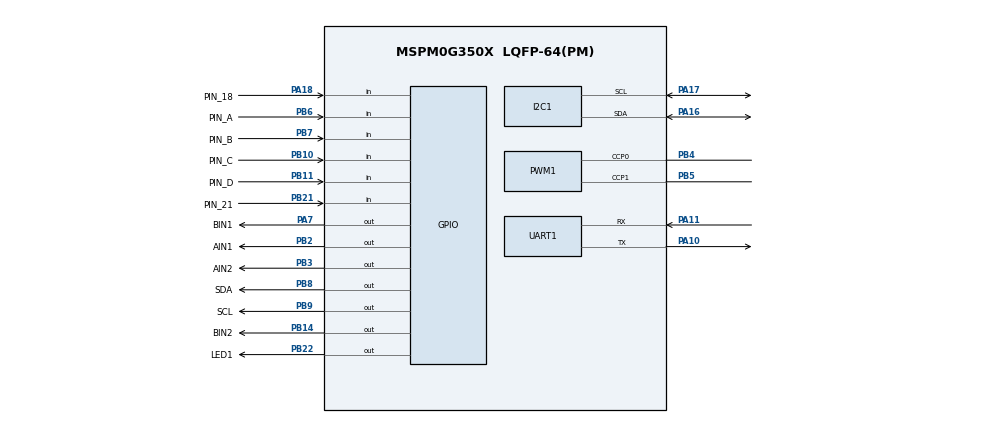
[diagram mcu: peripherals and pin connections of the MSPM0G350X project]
/**
 * @cliArgs --device "MSPM0G350X" --part "Default" --package "LQFP-64(PM)" --product "mspm0_sdk@2.03.00.07"
 * @versions {"tool":"1.22.0+3893"}
 */

/**
 * Import the modules used in this configuration.
 */
const GPIO    = scripting.addModule("/ti/driverlib/GPIO", {}, false);
const GPIO1   = GPIO.addInstance();
const GPIO2   = GPIO.addInstance();
const GPIO3   = GPIO.addInstance();
const GPIO4   = GPIO.addInstance();
const GPIO5   = GPIO.addInstance();
const I2C     = scripting.addModule("/ti/driverlib/I2C", {}, false);
const I2C1    = I2C.addInstance();
const PWM     = scripting.addModule("/ti/driverlib/PWM", {}, false);
const PWM1    = PWM.addInstance();
const SYSCTL  = scripting.addModule("/ti/driverlib/SYSCTL");
const SYSTICK = scripting.addModule("/ti/driverlib/SYSTICK");
const TIMER   = scripting.addModule("/ti/driverlib/TIMER", {}, false);
const TIMER1  = TIMER.addInstance();
const UART    = scripting.addModule("/ti/driverlib/UART", {}, false);
const UART1   = UART.addInstance();

/**
 * Write custom configuration values to the imported modules.
 */
const gate7  = system.clockTree["MFCLKGATE"];
gate7.enable = true;

GPIO1.$name                              = "LED";
GPIO1.associatedPins[0].internalResistor = "PULL_DOWN";
GPIO1.associatedPins[0].$name            = "LED1";
GPIO1.associatedPins[0].assignedPin      = "22";
GPIO1.associatedPins[0].pin.$assign      = "PB22";

const Board = scripting.addModule("/ti/driverlib/Board", {}, false);

GPIO2.$name                              = "KEY";
GPIO2.associatedPins.create(2);
GPIO2.associatedPins[0].$name            = "PIN_18";
GPIO2.associatedPins[0].direction        = "INPUT";
GPIO2.associatedPins[0].assignedPin      = "18";
GPIO2.associatedPins[0].internalResistor = "PULL_DOWN";
GPIO2.associatedPins[0].interruptEn      = true;
GPIO2.associatedPins[0].polarity         = "RISE";
GPIO2.associatedPins[0].assignedPort     = "PORTA";
GPIO2.associatedPins[0].pin.$assign      = "PA18";
GPIO2.associatedPins[1].$name            = "PIN_21";
GPIO2.associatedPins[1].direction        = "INPUT";
GPIO2.associatedPins[1].assignedPort     = "PORTB";
GPIO2.associatedPins[1].assignedPin      = "21";
GPIO2.associatedPins[1].internalResistor = "PULL_UP";
GPIO2.associatedPins[1].pin.$assign      = "PB21";

GPIO3.$name                          = "OLED";
GPIO3.port                           = "PORTB";
GPIO3.associatedPins.create(2);
GPIO3.associatedPins[0].$name        = "SCL";
GPIO3.associatedPins[0].initialValue = "SET";
GPIO3.associatedPins[0].assignedPin  = "9";
GPIO3.associatedPins[0].pin.$assign  = "PB9";
GPIO3.associatedPins[1].$name        = "SDA";
GPIO3.associatedPins[1].initialValue = "SET";
GPIO3.associatedPins[1].assignedPin  = "8";
GPIO3.associatedPins[1].pin.$assign  = "PB8";

GPIO4.$name                               = "GPIO_ENCODER";
GPIO4.associatedPins.create(4);
GPIO4.associatedPins[0].$name             = "PIN_A";
GPIO4.associatedPins[0].direction         = "INPUT";
GPIO4.associatedPins[0].assignedPort      = "PORTB";
GPIO4.associatedPins[0].assignedPin       = "6";
GPIO4.associatedPins[0].interruptEn       = true;
GPIO4.associatedPins[0].interruptPriority = "0";
GPIO4.associatedPins[0].polarity          = "RISE";
GPIO4.associatedPins[0].pin.$assign       = "PB6";
GPIO4.associatedPins[1].$name             = "PIN_B";
GPIO4.associatedPins[1].direction         = "INPUT";
GPIO4.associatedPins[1].assignedPort      = "PORTB";
GPIO4.associatedPins[1].assignedPin       = "7";
GPIO4.associatedPins[1].interruptEn       = true;
GPIO4.associatedPins[1].interruptPriority = "0";
GPIO4.associatedPins[1].polarity          = "RISE";
GPIO4.associatedPins[1].pin.$assign       = "PB7";
GPIO4.associatedPins[2].$name             = "PIN_C";
GPIO4.associatedPins[2].direction         = "INPUT";
GPIO4.associatedPins[2].interruptEn       = true;
GPIO4.associatedPins[2].polarity          = "RISE";
GPIO4.associatedPins[2].interruptPriority = "0";
GPIO4.associatedPins[2].assignedPort      = "PORTB";
GPIO4.associatedPins[2].assignedPin       = "10";
GPIO4.associatedPins[2].pin.$assign       = "PB10";
GPIO4.associatedPins[3].$name             = "PIN_D";
GPIO4.associatedPins[3].direction         = "INPUT";
GPIO4.associatedPins[3].assignedPort      = "PORTB";
GPIO4.associatedPins[3].interruptEn       = true;
GPIO4.associatedPins[3].polarity          = "RISE";
GPIO4.associatedPins[3].interruptPriority = "0";
GPIO4.associatedPins[3].assignedPin       = "11";
GPIO4.associatedPins[3].pin.$assign       = "PB11";

GPIO5.$name                          = "GPIO_MOTOR";
GPIO5.associatedPins.create(4);
GPIO5.associatedPins[0].$name        = "AIN1";
GPIO5.associatedPins[0].initialValue = "SET";
GPIO5.associatedPins[0].assignedPin  = "2";
GPIO5.associatedPins[0].assignedPort = "PORTB";
GPIO5.associatedPins[0].pin.$assign  = "PB2";
GPIO5.associatedPins[1].$name        = "AIN2";
GPIO5.associatedPins[1].assignedPort = "PORTB";
GPIO5.associatedPins[1].assignedPin  = "3";
GPIO5.associatedPins[1].initialValue = "SET";
GPIO5.associatedPins[1].pin.$assign  = "PB3";
GPIO5.associatedPins[2].$name        = "BIN1";
GPIO5.associatedPins[2].assignedPort = "PORTA";
GPIO5.associatedPins[2].assignedPin  = "7";
GPIO5.associatedPins[2].initialValue = "SET";
GPIO5.associatedPins[2].pin.$assign  = "PA7";
GPIO5.associatedPins[3].$name        = "BIN2";
GPIO5.associatedPins[3].assignedPort = "PORTB";
GPIO5.associatedPins[3].assignedPin  = "14";
GPIO5.associatedPins[3].initialValue = "SET";
GPIO5.associatedPins[3].pin.$assign  = "PB14";

I2C1.$name                     = "I2C_0";
I2C1.basicEnableController     = true;
I2C1.peripheral.$assign        = "I2C1";
I2C1.peripheral.sdaPin.$assign = "PA16";
I2C1.peripheral.sclPin.$assign = "PA17";
I2C1.sdaPinConfig.$name        = "ti_driverlib_gpio_GPIOPinGeneric2";
I2C1.sclPinConfig.$name        = "ti_driverlib_gpio_GPIOPinGeneric3";

PWM1.$name                      = "PWM_0";
PWM1.timerStartTimer            = true;
PWM1.clockDivider               = 4;
PWM1.clockPrescale              = 2;
PWM1.peripheral.$assign         = "TIMA1";
PWM1.peripheral.ccp0Pin.$assign = "PB4";
PWM1.peripheral.ccp1Pin.$assign = "PB5";
PWM1.PWM_CHANNEL_0.$name        = "ti_driverlib_pwm_PWMTimerCC0";
PWM1.PWM_CHANNEL_1.$name        = "ti_driverlib_pwm_PWMTimerCC1";
PWM1.ccp0PinConfig.$name        = "ti_driverlib_gpio_GPIOPinGeneric4";
PWM1.ccp1PinConfig.$name        = "ti_driverlib_gpio_GPIOPinGeneric5";

SYSCTL.forceDefaultClkConfig = true;
SYSCTL.clockTreeEn           = true;

SYSTICK.periodEnable      = true;
SYSTICK.systickEnable     = true;
SYSTICK.interruptPriority = "0";
SYSTICK.period            = 32;

TIMER1.$name              = "TIMER_TICK";
TIMER1.timerStartTimer    = true;
TIMER1.timerPeriod        = "10 ms";
TIMER1.interrupts         = ["ZERO"];
TIMER1.timerClkPrescale   = 32;
TIMER1.timerMode          = "PERIODIC";
TIMER1.interruptPriority  = "3";
TIMER1.peripheral.$assign = "TIMA0";

UART1.$name                    = "UART_0";
UART1.uartClkSrc               = "MFCLK";
UART1.enabledInterrupts        = ["RX"];
UART1.targetBaudRate           = 115200;
UART1.peripheral.$assign       = "UART0";
UART1.peripheral.rxPin.$assign = "PA11";
UART1.peripheral.txPin.$assign = "PA10";
UART1.txPinConfig.$name        = "ti_driverlib_gpio_GPIOPinGeneric0";
UART1.rxPinConfig.$name        = "ti_driverlib_gpio_GPIOPinGeneric1";

/**
 * Pinmux solution for unlocked pins/peripherals. This ensures that minor changes to the automatic solver in a future
 * version of the tool will not impact the pinmux you originally saw.  These lines can be completely deleted in order to
 * re-solve from scratch.
 */
Board.peripheral.$suggestSolution          = "DEBUGSS";
Board.peripheral.swclkPin.$suggestSolution = "PA20";
Board.peripheral.swdioPin.$suggestSolution = "PA19";
